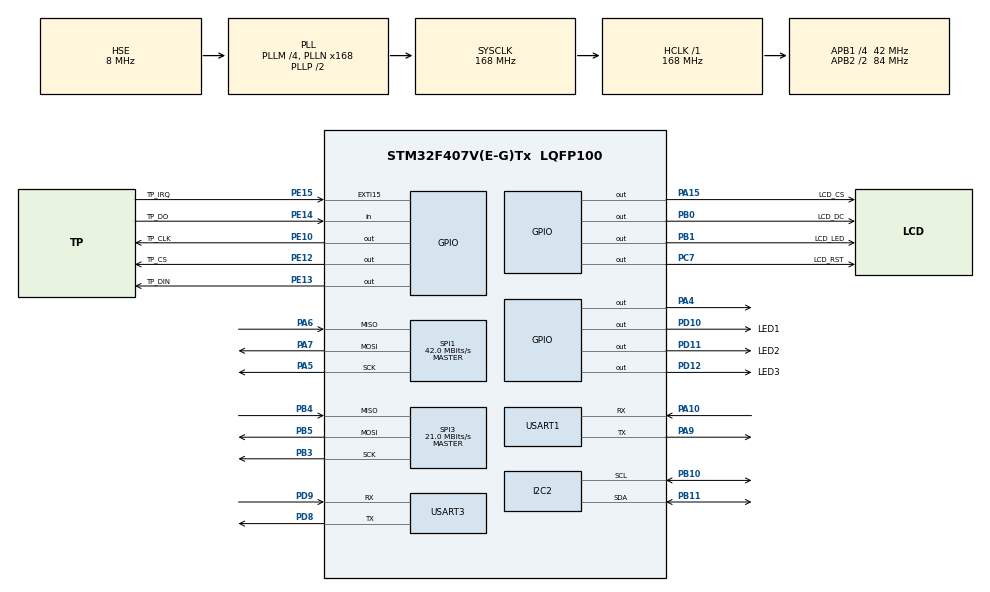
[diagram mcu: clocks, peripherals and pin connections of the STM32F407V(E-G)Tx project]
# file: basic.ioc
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Dma.I2C2_RX.0.Direction=DMA_PERIPH_TO_MEMORY
Dma.I2C2_RX.0.FIFOMode=DMA_FIFOMODE_DISABLE
Dma.I2C2_RX.0.Instance=DMA1_Stream2
Dma.I2C2_RX.0.MemDataAlignment=DMA_MDATAALIGN_BYTE
Dma.I2C2_RX.0.MemInc=DMA_MINC_ENABLE
Dma.I2C2_RX.0.Mode=DMA_NORMAL
Dma.I2C2_RX.0.PeriphDataAlignment=DMA_PDATAALIGN_BYTE
Dma.I2C2_RX.0.PeriphInc=DMA_PINC_DISABLE
Dma.I2C2_RX.0.Priority=DMA_PRIORITY_LOW
Dma.I2C2_TX.1.Direction=DMA_MEMORY_TO_PERIPH
Dma.I2C2_TX.1.FIFOMode=DMA_FIFOMODE_DISABLE
Dma.I2C2_TX.1.Instance=DMA1_Stream7
Dma.I2C2_TX.1.MemDataAlignment=DMA_MDATAALIGN_BYTE
Dma.I2C2_TX.1.MemInc=DMA_MINC_ENABLE
Dma.I2C2_TX.1.Mode=DMA_NORMAL
Dma.I2C2_TX.1.PeriphDataAlignment=DMA_PDATAALIGN_BYTE
Dma.I2C2_TX.1.PeriphInc=DMA_PINC_DISABLE
Dma.I2C2_TX.1.Priority=DMA_PRIORITY_LOW
Dma.Request0=I2C2_RX
Dma.Request1=I2C2_TX
Dma.Request2=SPI3_RX
Dma.Request3=SPI3_TX
Dma.SPI3_RX.2.Direction=DMA_PERIPH_TO_MEMORY
Dma.SPI3_RX.2.FIFOMode=DMA_FIFOMODE_DISABLE
Dma.SPI3_RX.2.Instance=DMA1_Stream0
Dma.SPI3_RX.2.MemDataAlignment=DMA_MDATAALIGN_BYTE
Dma.SPI3_RX.2.MemInc=DMA_MINC_ENABLE
Dma.SPI3_RX.2.Mode=DMA_NORMAL
Dma.SPI3_RX.2.PeriphDataAlignment=DMA_PDATAALIGN_BYTE
Dma.SPI3_RX.2.PeriphInc=DMA_PINC_DISABLE
Dma.SPI3_RX.2.Priority=DMA_PRIORITY_LOW
Dma.SPI3_TX.3.Direction=DMA_MEMORY_TO_PERIPH
Dma.SPI3_TX.3.FIFOMode=DMA_FIFOMODE_DISABLE
Dma.SPI3_TX.3.Instance=DMA1_Stream5
Dma.SPI3_TX.3.MemDataAlignment=DMA_MDATAALIGN_BYTE
Dma.SPI3_TX.3.MemInc=DMA_MINC_ENABLE
Dma.SPI3_TX.3.Mode=DMA_NORMAL
Dma.SPI3_TX.3.PeriphDataAlignment=DMA_PDATAALIGN_BYTE
Dma.SPI3_TX.3.PeriphInc=DMA_PINC_DISABLE
Dma.SPI3_TX.3.Priority=DMA_PRIORITY_LOW
FREERTOS.Tasks01=defaultTask,24,128,StartDefaultTask,Default,NULL,Dynamic,NULL,NULL
Mcu.Family=STM32F4
Mcu.Name=STM32F407V(E-G)Tx
Mcu.Package=LQFP100
NVIC.DMA1_Stream0_IRQn=true\:5\:0\:false\:false\:true\:true\:false\:true\:true
NVIC.DMA1_Stream2_IRQn=true\:5\:0\:false\:false\:true\:true\:false\:true\:true
NVIC.DMA1_Stream5_IRQn=true\:5\:0\:false\:false\:true\:true\:false\:true\:true
NVIC.DMA1_Stream7_IRQn=true\:5\:0\:false\:false\:true\:true\:false\:true\:true
NVIC.EXTI15_10_IRQn=true\:5\:0\:false\:false\:true\:true\:true\:true\:true
NVIC.I2C2_EV_IRQn=true\:5\:0\:false\:false\:true\:true\:true\:true\:true
NVIC.PriorityGroup=NVIC_PRIORITYGROUP_4
NVIC.SPI1_IRQn=true\:5\:0\:false\:false\:true\:true\:true\:true\:true
NVIC.SPI3_IRQn=true\:5\:0\:false\:false\:true\:true\:true\:true\:true
NVIC.TIM1_UP_TIM10_IRQn=true\:15\:0\:false\:false\:true\:false\:false\:true\:true
NVIC.TimeBase=TIM1_UP_TIM10_IRQn
NVIC.TimeBaseIP=TIM1
NVIC.USART1_IRQn=true\:5\:0\:false\:false\:true\:true\:true\:true\:true
NVIC.USART3_IRQn=true\:5\:0\:false\:false\:true\:true\:true\:true\:true
PA10.Mode=Asynchronous
PA10.Signal=USART1_RX
PA13.Mode=Serial_Wire
PA13.Signal=SYS_JTMS-SWDIO
PA14.Mode=Serial_Wire
PA14.Signal=SYS_JTCK-SWCLK
PA15.GPIO_Label=LCD_CS
PA15.PinState=GPIO_PIN_SET
PA15.Signal=GPIO_Output
PA4.PinState=GPIO_PIN_SET
PA4.Signal=GPIO_Output
PA5.Mode=Full_Duplex_Master
PA5.Signal=SPI1_SCK
PA6.Mode=Full_Duplex_Master
PA6.Signal=SPI1_MISO
PA7.Mode=Full_Duplex_Master
PA7.Signal=SPI1_MOSI
PA9.Mode=Asynchronous
PA9.Signal=USART1_TX
PB0.GPIO_Label=LCD_DC
PB0.GPIO_Speed=GPIO_SPEED_FREQ_HIGH
PB0.Signal=GPIO_Output
PB1.GPIO_Label=LCD_LED
PB1.Signal=GPIO_Output
PB10.Mode=I2C
PB10.Signal=I2C2_SCL
PB11.Mode=I2C
PB11.Signal=I2C2_SDA
PB3.Mode=Full_Duplex_Master
PB3.Signal=SPI3_SCK
PB4.Mode=Full_Duplex_Master
PB4.Signal=SPI3_MISO
PB5.Mode=Full_Duplex_Master
PB5.Signal=SPI3_MOSI
PC14-OSC32_IN.Mode=LSE-External-Oscillator
PC14-OSC32_IN.Signal=RCC_OSC32_IN
PC15-OSC32_OUT.Mode=LSE-External-Oscillator
PC15-OSC32_OUT.Signal=RCC_OSC32_OUT
PC7.GPIO_Label=LCD_RST
PC7.Signal=GPIO_Output
PD10.GPIO_Label=LED1
PD10.Signal=GPIO_Output
PD11.GPIO_Label=LED2
PD11.Signal=GPIO_Output
PD12.GPIO_Label=LED3
PD12.Signal=GPIO_Output
PD8.Mode=Asynchronous
PD8.Signal=USART3_TX
PD9.Mode=Asynchronous
PD9.Signal=USART3_RX
PE10.GPIO_Label=TP_CLK
PE10.GPIO_Speed=GPIO_SPEED_FREQ_HIGH
PE10.Signal=GPIO_Output
PE12.GPIO_Label=TP_CS
PE12.GPIO_Speed=GPIO_SPEED_FREQ_HIGH
PE12.PinState=GPIO_PIN_SET
PE12.Signal=GPIO_Output
PE13.GPIO_Label=TP_DIN
PE13.GPIO_Speed=GPIO_SPEED_FREQ_HIGH
PE13.Signal=GPIO_Output
PE14.GPIO_Label=TP_DO
PE14.GPIO_PuPd=GPIO_PULLUP
PE14.Signal=GPIO_Input
PE15.GPIO_Label=TP_IRQ
PE15.GPIO_ModeDefaultEXTI=GPIO_MODE_IT_FALLING
PE15.GPIO_PuPd=GPIO_PULLUP
PE15.Signal=GPXTI15
PH0-OSC_IN.Mode=HSE-External-Oscillator
PH0-OSC_IN.Signal=RCC_OSC_IN
PH1-OSC_OUT.Mode=HSE-External-Oscillator
PH1-OSC_OUT.Signal=RCC_OSC_OUT
ProjectManager.HeapSize=0x2000
ProjectManager.StackSize=0x2000
ProjectManager.TargetToolchain=MDK-ARM V5.32
RCC.48MHZClocksFreq_Value=84000000
RCC.AHBFreq_Value=168000000
RCC.APB1CLKDivider=RCC_HCLK_DIV4
RCC.APB1Freq_Value=42000000
RCC.APB1TimFreq_Value=84000000
RCC.APB2CLKDivider=RCC_HCLK_DIV2
RCC.APB2Freq_Value=84000000
RCC.APB2TimFreq_Value=168000000
RCC.CortexFreq_Value=168000000
RCC.HCLKFreq_Value=168000000
RCC.HSE_VALUE=8000000
RCC.HSI_VALUE=16000000
RCC.PLLM=4
RCC.PLLN=168
RCC.PLLSourceVirtual=RCC_PLLSOURCE_HSE
RCC.SYSCLKFreq_VALUE=168000000
RCC.SYSCLKSource=RCC_SYSCLKSOURCE_PLLCLK
RCC.VCOOutputFreq_Value=336000000
SPI1.CalculateBaudRate=42.0 MBits/s
SPI1.Direction=SPI_DIRECTION_2LINES
SPI1.Mode=SPI_MODE_MASTER
SPI1.VirtualType=VM_MASTER
SPI3.CalculateBaudRate=21.0 MBits/s
SPI3.Direction=SPI_DIRECTION_2LINES
SPI3.Mode=SPI_MODE_MASTER
SPI3.VirtualType=VM_MASTER
USART1.VirtualMode=VM_ASYNC
USART3.VirtualMode=VM_ASYNC
VP_FREERTOS_VS_CMSIS_V2.Mode=CMSIS_V2
VP_SYS_VS_tim1.Mode=TIM1
board=custom

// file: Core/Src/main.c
/* USER CODE BEGIN Header */
/**
  ******************************************************************************
  * @file           : main.c
  * @brief          : Main program body
  ******************************************************************************
  * @attention
  *
  * Copyright (c) 2026 STMicroelectronics.
  * All rights reserved.
  *
  * This software is licensed under terms that can be found in the LICENSE file
  * in the root directory of this software component.
  * If no LICENSE file comes with this software, it is provided AS-IS.
  *
  ******************************************************************************
  */
/* USER CODE END Header */
#include "main.h"
#include "cmsis_os.h"
#include "dma.h"
#include "i2c.h"
#include "spi.h"
#include "usart.h"
#include "gpio.h"

void SystemClock_Config(void);
void MX_FREERTOS_Init(void);

int main(void)
{

  /* MCU Configuration--------------------------------------------------------*/

  /* Reset of all peripherals, Initializes the Flash interface and the Systick. */
  HAL_Init();

  /* Configure the system clock */
  SystemClock_Config();

  /* Initialize all configured peripherals */
  MX_GPIO_Init();
  MX_DMA_Init();
  MX_USART1_UART_Init();
  MX_I2C2_Init();
  MX_SPI1_Init();
  MX_USART3_UART_Init();
  MX_SPI3_Init();
  /* USER CODE BEGIN 2 */
    extern void app_test();
    app_test();
    //HAL_GPIO_WritePin(GPIOD, GPIO_PIN_10,GPIO_PIN_SET);
  /* USER CODE END 2 */

  /* Init scheduler */
  osKernelInitialize();  /* Call init function for freertos objects (in freertos.c) */
  MX_FREERTOS_Init();

  /* Start scheduler */
  osKernelStart();

  /* We should never get here as control is now taken by the scheduler */
  /* Infinite loop */
  while (1)
  {

  }
}

void SystemClock_Config(void)
{
  RCC_OscInitTypeDef RCC_OscInitStruct = {0};
  RCC_ClkInitTypeDef RCC_ClkInitStruct = {0};

  /** Configure the main internal regulator output voltage
  */
  __HAL_RCC_PWR_CLK_ENABLE();
  __HAL_PWR_VOLTAGESCALING_CONFIG(PWR_REGULATOR_VOLTAGE_SCALE1);

  /** Initializes the RCC Oscillators according to the specified parameters
  * in the RCC_OscInitTypeDef structure.
  */
  RCC_OscInitStruct.OscillatorType = RCC_OSCILLATORTYPE_HSE;
  RCC_OscInitStruct.HSEState = RCC_HSE_ON;
  RCC_OscInitStruct.PLL.PLLState = RCC_PLL_ON;
  RCC_OscInitStruct.PLL.PLLSource = RCC_PLLSOURCE_HSE;
  RCC_OscInitStruct.PLL.PLLM = 4;
  RCC_OscInitStruct.PLL.PLLN = 168;
  RCC_OscInitStruct.PLL.PLLP = RCC_PLLP_DIV2;
  RCC_OscInitStruct.PLL.PLLQ = 4;
  if (HAL_RCC_OscConfig(&RCC_OscInitStruct) != HAL_OK)
  {
    Error_Handler();
  }

  /** Initializes the CPU, AHB and APB buses clocks
  */
  RCC_ClkInitStruct.ClockType = RCC_CLOCKTYPE_HCLK|RCC_CLOCKTYPE_SYSCLK
                              |RCC_CLOCKTYPE_PCLK1|RCC_CLOCKTYPE_PCLK2;
  RCC_ClkInitStruct.SYSCLKSource = RCC_SYSCLKSOURCE_PLLCLK;
  RCC_ClkInitStruct.AHBCLKDivider = RCC_SYSCLK_DIV1;
  RCC_ClkInitStruct.APB1CLKDivider = RCC_HCLK_DIV4;
  RCC_ClkInitStruct.APB2CLKDivider = RCC_HCLK_DIV2;

  if (HAL_RCC_ClockConfig(&RCC_ClkInitStruct, FLASH_LATENCY_5) != HAL_OK)
  {
    Error_Handler();
  }
}

void HAL_TIM_PeriodElapsedCallback(TIM_HandleTypeDef *htim)
{
  if (htim->Instance == TIM1) {
    HAL_IncTick();
  }
}

void Error_Handler(void)
{
  __disable_irq();
  while (1)
  {
  }
}
